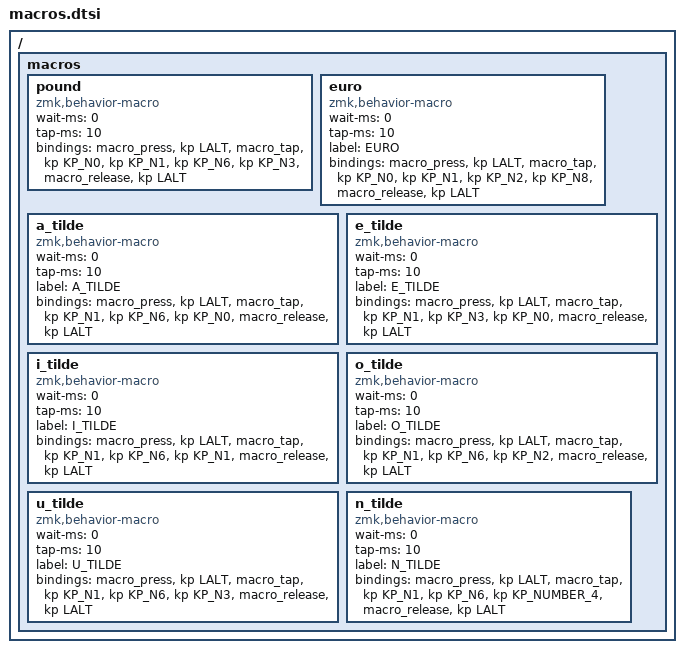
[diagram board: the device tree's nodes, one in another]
/ {
    macros {
        pound: pound {
            compatible = "zmk,behavior-macro";
            #binding-cells = <0>;
            wait-ms = <0>;
            tap-ms = <10>;
            bindings =
                <&macro_press>,
                <&kp LALT>,
                <&macro_tap>,
                <&kp KP_N0 &kp KP_N1 &kp KP_N6 &kp KP_N3>,
                <&macro_release>,
                <&kp LALT>;
        };

        euro: euro {
            compatible = "zmk,behavior-macro";
            #binding-cells = <0>;
            wait-ms = <0>;
            tap-ms = <10>;
            label = "EURO";
            bindings =
                <&macro_press>,
                <&kp LALT>,
                <&macro_tap>,
                <&kp KP_N0 &kp KP_N1 &kp KP_N2 &kp KP_N8>,
                <&macro_release>,
                <&kp LALT>;
        };

        a_tilde: a_tilde {
            compatible = "zmk,behavior-macro";
            #binding-cells = <0>;
            wait-ms = <0>;
            tap-ms = <10>;
            label = "A_TILDE";
            bindings =
                <&macro_press>,
                <&kp LALT>,
                <&macro_tap>,
                <&kp KP_N1 &kp KP_N6 &kp KP_N0>,
                <&macro_release>,
                <&kp LALT>;
        };

        e_tilde: e_tilde {
            compatible = "zmk,behavior-macro";
            #binding-cells = <0>;
            wait-ms = <0>;
            tap-ms = <10>;
            label = "E_TILDE";
            bindings =
                <&macro_press>,
                <&kp LALT>,
                <&macro_tap>,
                <&kp KP_N1 &kp KP_N3 &kp KP_N0>,
                <&macro_release>,
                <&kp LALT>;
        };

        i_tilde: i_tilde {
            compatible = "zmk,behavior-macro";
            #binding-cells = <0>;
            wait-ms = <0>;
            tap-ms = <10>;
            label = "I_TILDE";
            bindings =
                <&macro_press>,
                <&kp LALT>,
                <&macro_tap>,
                <&kp KP_N1 &kp KP_N6 &kp KP_N1>,
                <&macro_release>,
                <&kp LALT>;
        };

        o_tilde: o_tilde {
            compatible = "zmk,behavior-macro";
            #binding-cells = <0>;
            wait-ms = <0>;
            tap-ms = <10>;
            label = "O_TILDE";
            bindings =
                <&macro_press>,
                <&kp LALT>,
                <&macro_tap>,
                <&kp KP_N1 &kp KP_N6 &kp KP_N2>,
                <&macro_release>,
                <&kp LALT>;
        };

        u_tilde: u_tilde {
            compatible = "zmk,behavior-macro";
            #binding-cells = <0>;
            wait-ms = <0>;
            tap-ms = <10>;
            label = "U_TILDE";
            bindings =
                <&macro_press>,
                <&kp LALT>,
                <&macro_tap>,
                <&kp KP_N1 &kp KP_N6 &kp KP_N3>,
                <&macro_release>,
                <&kp LALT>;
        };

        n_tilde: n_tilde {
            compatible = "zmk,behavior-macro";
            #binding-cells = <0>;
            wait-ms = <0>;
            tap-ms = <10>;
            label = "N_TILDE";
            bindings =
                <&macro_press>,
                <&kp LALT>,
                <&macro_tap>,
                <&kp KP_N1 &kp KP_N6 &kp KP_NUMBER_4>,
                <&macro_release>,
                <&kp LALT>;
        };
    };
};
